# A31L12x register map
Vendor: VENDOR ABOV Semiconductor Co., Ltd.; Series: A31L12x; File version: 1.0
CPU: CM0+ r0p1, little endian, no MPU, no FPU, VTOR, 2 interrupt priority bits
Registers are 32-bit, read-write, reset 0x0 unless marked. A register's access mark holds for its fields unless they carry their own. Offsets are from the block's base; [hi:lo] are bit positions; {n}, {i} and the like mark numbered series; 'fields as' and 'values as' point back to an identical list.

## CMP0 — Comparator 0
Base 0x40005600
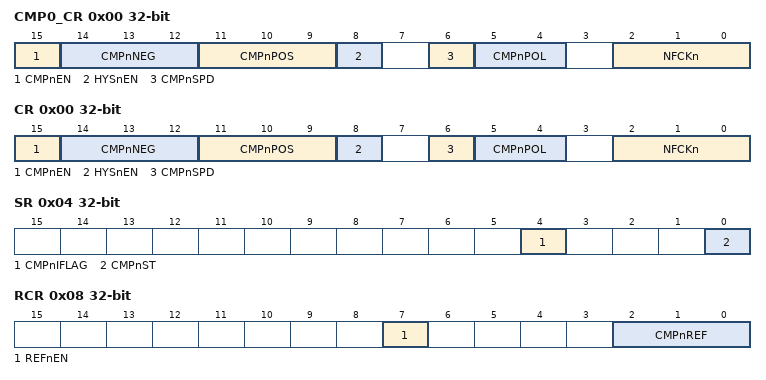
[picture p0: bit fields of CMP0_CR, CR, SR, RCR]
0x00 CMP0_CR (alternate view of CR) — Comparator 0 Control Register
  [15] CMPnEN — Comparator n Enable
    0=Disable comparator n operation; 1=Enable comparator n operation
  [14:12] CMPnNEG — Comparator n Negative Input Selection
    0=CPnN0 (Select external CPnN0 pin.); 1=CPnN1 (Select external CPnN1 pin.); 2=CPnN2 (Select external CPnN2 pin.); 7=IntRef (Select internal reference.)
  [11:9] CMPnPOS — Comparator n Positive Input Selection
    0=CPnP0 (Select external CPnP0 pin.); 1=CPnP1 (Select external CPnP1 pin. (CP1POS signal on comparator 0))
  [8] HYSnEN — Comparator n Hysteresis Enable
    0=Disable hysteresis function; 1=Enable hysteresis function
  [6] CMPnSPD — Comparator n Speed Selection
    0=Slow speed; 1=Fast speed
  [5:4] CMPnPOL — Comparator n Interrupt Polarity Selection
    0=No interrupt at any edge; 1=FallingEdge (Interrupt on falling edge); 2=RisingEdge (Interrupt on rising edge); 3=BothEdge (Interrupt on both of falling and rising edge)
  [2:0] NFCKn — Comparator n Noise Filter Sampling Clock Selection
    0=PCLK1; 1=PCLK2; 2=PCLK4; 3=PCLK8; 4=PCLK16; 5=PCLK32; 6=PCLK64
0x00 CR — Comparator n Control Register
  [15] CMPnEN — Comparator n Enable
    values as CMP0_CR.CMPnEN
  [14:12] CMPnNEG — Comparator n Negative Input Selection
    0=CPnN0 (Select external CPnN0 pin.); 1=CPnN1 (Select external CPnN1 pin.); 2=CPnN2 (Select external CPnN2 pin.); 3=CPnN3 (Select external CPnN3 pin. (Reserved on comparator 0)); 7=IntRef (Select internal reference.)
  [11:9] CMPnPOS — Comparator n Positive Input Selection
    0=CPnP0 (Select external CPnP0 pin.); 1=CPnP1 (Select external CPnP1 pin. (CP1POS signal on comparator 0)); {v}=CPnP{v} (Select external CPnP{v} pin. (Reserved on comparator 0)) (v=2..5)
  [8] HYSnEN — Comparator n Hysteresis Enable
    0=Disable hysteresis function; 1=Enable hysteresis function
  [6] CMPnSPD — Comparator n Speed Selection
    0=Slow speed; 1=Fast speed
  [5:4] CMPnPOL — Comparator n Interrupt Polarity Selection
    values as CMP0_CR.CMPnPOL
  [2:0] NFCKn — Comparator n Noise Filter Sampling Clock Selection
    values as CMP0_CR.NFCKn
0x04 SR — Comparator n Status Register
  [4] CMPnIFLAG — Comparator n Interrupt Flag
    0=No request occurred; 1=Request occurred. This bit is cleared to '0' when write '1'.
  [0] CMPnST ro — Comparator n Output Status
    0=Low (Comparator n output is low.); 1=High (Comparator n output is high.)
0x08 RCR — Comparator n Reference Control Register
  [7] REFnEN — Comparator n Internal Reference Enable
    0=Disable internal reference; 1=Enable internal reference
  [2:0] CMPnREF — Comparator n Reference Voltage Level Selection
    {v}={v+2}over11VDD (Select reference voltage level {v}. NOTE) Reference voltage = (2+k)xVDD/11, k: 0 to 7) (v=0..7)

## CMP1 — Comparator 1
Base 0x40005680
Registers as CMP0 (with CMP0 read as CMP1); these are added or differ:
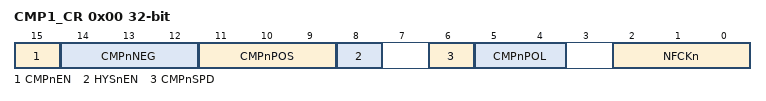
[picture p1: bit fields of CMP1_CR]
0x00 CMP1_CR (alternate view of CR) — Comparator 1 Control Register
  [15] CMPnEN — Comparator n Enable
    0=Disable comparator n operation; 1=Enable comparator n operation
  [14:12] CMPnNEG — Comparator n Negative Input Selection
    {v}=CPnN{v} (Select external CPnN{v} pin.) (v=0..3); 7=IntRef (Select internal reference.)
  [11:9] CMPnPOS — Comparator n Positive Input Selection
    0=CPnP0 (Select external CPnP0 pin.); 1=CPnP1 (Select external CPnP1 pin. (CP1POS signal on comparator 0)); 2=CPnP2 (Select external CPnP2 pin.); 3=CPnP3 (Select external CPnP3 pin.); 4=CPnP4 (Select external CPnP4 pin); 5=CPnP5 (Select external CPnP5 pin.)
  [8] HYSnEN — Comparator n Hysteresis Enable
    0=Disable hysteresis function; 1=Enable hysteresis function
  [6] CMPnSPD — Comparator n Speed Selection
    0=Slow speed; 1=Fast speed
  [5:4] CMPnPOL — Comparator n Interrupt Polarity Selection
    0=No interrupt at any edge; 1=FallingEdge (Interrupt on falling edge); 2=RisingEdge (Interrupt on rising edge); 3=BothEdge (Interrupt on both of falling and rising edge)
  [2:0] NFCKn — Comparator n Noise Filter Sampling Clock Selection
    0=PCLK1; 1=PCLK2; 2=PCLK4; 3=PCLK8; 4=PCLK16; 5=PCLK32; 6=PCLK64
